# ESP32-P4 register map
Vendor: ESPRESSIF SYSTEMS (SHANGHAI) CO., LTD.; Series: ESP32 P-Series; File version: 2
CPU: RV32IMAFC r0p0, little endian, no MPU, FPU, 0 interrupt priority bits
Address unit: 32 bits
Registers are 32-bit, read-write, reset 0x0 unless marked. A register's access mark holds for its fields unless they carry their own. Offsets are from the block's base; [hi:lo] are bit positions; {n}, {i} and the like mark numbered series.

## LP_HUK — LP_HUK Peripheral
Base 0x50114000
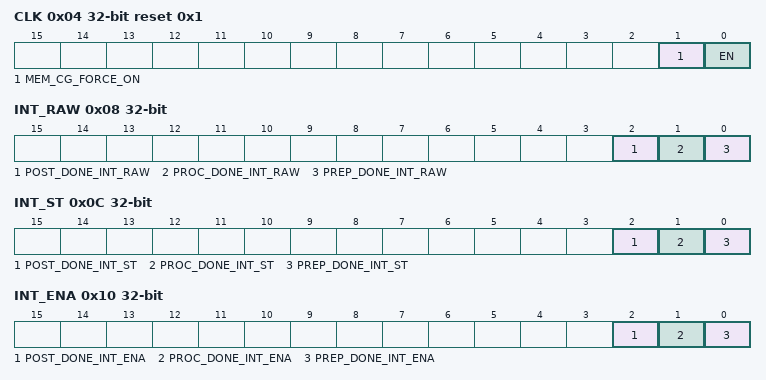
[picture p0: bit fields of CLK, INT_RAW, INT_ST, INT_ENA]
0x04 CLK reset 0x1 — HUK Generator clock gate control register
  [1] MEM_CG_FORCE_ON — Write 1 to force on memory clock gate.
  [0] EN — Write 1 to force on register clock gate.
0x08 INT_RAW ro — HUK Generator interrupt raw register, valid in level.
  [2] POST_DONE_INT_RAW — The raw interrupt status bit for the huk_post_done_int interrupt
  [1] PROC_DONE_INT_RAW — The raw interrupt status bit for the huk_proc_done_int interrupt
  [0] PREP_DONE_INT_RAW — The raw interrupt status bit for the huk_prep_done_int interrupt
0x0C INT_ST ro — HUK Generator interrupt status register.
  [2] POST_DONE_INT_ST — The masked interrupt status bit for the huk_post_done_int interrupt
  [1] PROC_DONE_INT_ST — The masked interrupt status bit for the huk_proc_done_int interrupt
  [0] PREP_DONE_INT_ST — The masked interrupt status bit for the huk_prep_done_int interrupt
0x10 INT_ENA — HUK Generator interrupt enable register.
  [2] POST_DONE_INT_ENA — The interrupt enable bit for the huk_post_done_int interrupt
  [1] PROC_DONE_INT_ENA — The interrupt enable bit for the huk_proc_done_int interrupt
  [0] PREP_DONE_INT_ENA — The interrupt enable bit for the huk_prep_done_int interrupt
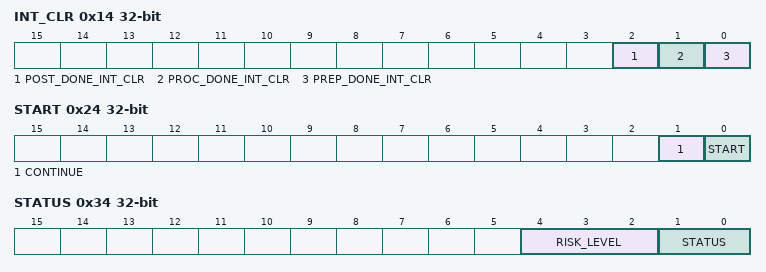
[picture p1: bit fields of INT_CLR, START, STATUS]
0x14 INT_CLR wo — HUK Generator interrupt clear register.
  [2] POST_DONE_INT_CLR — Set this bit to clear the huk_post_done_int interrupt
  [1] PROC_DONE_INT_CLR — Set this bit to clear the huk_proc_done_int interrupt
  [0] PREP_DONE_INT_CLR — Set this bit to clear the huk_prep_done_int interrupt
0x20 CONF — HUK Generator configuration register
  [0] MODE — Set this field to choose the huk process. 1: process huk generate mode. 0: process huk recovery mode.
0x24 START wo — HUK Generator control register
  [1] CONTINUE — Write 1 to start HUK Generator at IDLE state.
  [0] START — Write 1 to continue HUK Generator operation at LOAD/GAIN state.
0x28 STATE ro — HUK Generator state register
  [1:0] STATE — The state of HUK Generator. 0: IDLE. 1: LOAD. 2: GAIN. 3: BUSY.
0x34 STATUS ro — HUK Generator HUK status register
  [4:2] RISK_LEVEL — The risk level of HUK. 0-6: the higher the risk level is, the more error bits there are in the PUF SRAM. 7: Error Level, HUK is invalid.
  [1:0] STATUS — The HUK generation status. 0: HUK is not generated. 1: HUK is generated and valid. 2: HUK is generated but invalid. 3: reserved.
0xFC DATE reset 0x2305040 — Version control register
  [27:0] DATE — HUK Generator version control register.
{0x100+4i} INFO_MEM[{i}] (i=0..95) access not given — The memory that stores HUK info.

## I3C_MST_MEM — I3C_MST_MEM Peripheral
Base 0x500DA000
0x08 COMMAND_BUF_PORT
  [31:0] REG_COMMAND — Contains a Command Descriptor structure that depends on the requested transfer type. Command Descriptor structure is used to schedule the transfers to devices on I3C bus.
0x0C RESPONSE_BUF_PORT ro
  [31:0] RESPONSE — The Response Buffer can be read through this register. The response status for each Command is written into the Response Buffer by the controller if ROC (Response On Completion) bit is set or if transfer error has occurred. The response buffer can be read through this register.
0x10 RX_DATA_PORT ro
  [31:0] RX_DATA_PORT — Receive Data Port. Receive data is mapped to the Rx-data buffer and receive data is always packed in 4-byte aligned data words. If the length of data transfer is not aligned to 4-bytes boundary, then there will be extra(unused) bytes(the additional data bytes have to be ignored) at the end of the transferred data. The valid data must be identified using the DATA_LENGTH filed in the Response Descriptor.
0x14 TX_DATA_PORT
  [31:0] REG_TX_DATA_PORT — Transmit Data Port. Transmit data is mapped to the Tx-data buffer and transmit data is always packed in 4-byte aligned data words. If the length of data transfer is not aligned to 4-bytes boundary, then there will be extra(unused) bytes(the additional data bytes have to be ignored) at the end of the transferred data. The valid data must be identified using the DATA_LENGTH filed in the Response Descriptor.
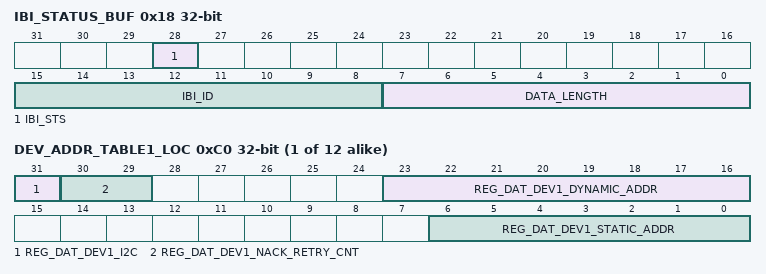
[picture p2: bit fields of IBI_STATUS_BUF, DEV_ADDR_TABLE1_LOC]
0x18 IBI_STATUS_BUF ro — In-Band Interrupt Buffer Status/Data Register. When receiving an IBI, IBI_PORT is used to both: Read the IBI Status Read the IBI Data(which is raw/opaque data)
  [28] IBI_STS — IBI received data/status. IBI Data register is mapped to the IBI Buffer. The IBI Data is always packed in4-byte aligned and put to the IBI Buffer. This register When read from, reads the data from the IBI buffer. IBI Status register when read from, returns the data from the IBI Buffer and indicates how the controller responded to incoming IBI(SIR, MR and HJ).
  [15:8] IBI_ID — IBI Identifier. The byte received after START which includes the address the R/W bit: Device address and R/W bit in case of Slave Interrupt or Master Request.
  [7:0] DATA_LENGTH — This field represents the length of data received along with IBI, in bytes.
0x40 IBI_DATA_BUF ro
  [31:0] IBI_DATA
{0xBC+4i} DEV_ADDR_TABLE{i}_LOC (i=1..12)
  [31] REG_DAT_DEV{i}_I2C — Legacy I2C device or not. This bit should be set to 1 if the device is a legacy I2C device.
  [30:29] REG_DAT_DEV{i}_NACK_RETRY_CNT — This field is used to set the Device NACK Retry count for the particular device. If the Device NACK's for the device address, the controller automatically retries the same device until this count expires. If the Slave does not ACK for the mentioned number of retries, then controller generates an error response and move to the Halt state.
  [23:16] REG_DAT_DEV{i}_DYNAMIC_ADDR — Device Dynamic Address with parity, The MSB,bit[23], should be programmed with parity of dynamic address.
  [6:0] REG_DAT_DEV{i}_STATIC_ADDR
{0xF0+0x10*i} DEV_CHAR_TABLE{i}_LOC1 ro (i=1..12)
  [31:0] DCT_DEV{i}_LOC1
{0xF4+0x10*i} DEV_CHAR_TABLE{i}_LOC2 ro (i=1..12)
  [31:0] DCT_DEV{i}_LOC2
{0xF8+0x10*i} DEV_CHAR_TABLE{i}_LOC3 ro (i=1..12)
  [31:0] DCT_DEV{i}_LOC3
{0xFC+0x10*i} DEV_CHAR_TABLE{i}_LOC4 ro (i=1..12)
  [31:0] DCT_DEV{i}_LOC4
